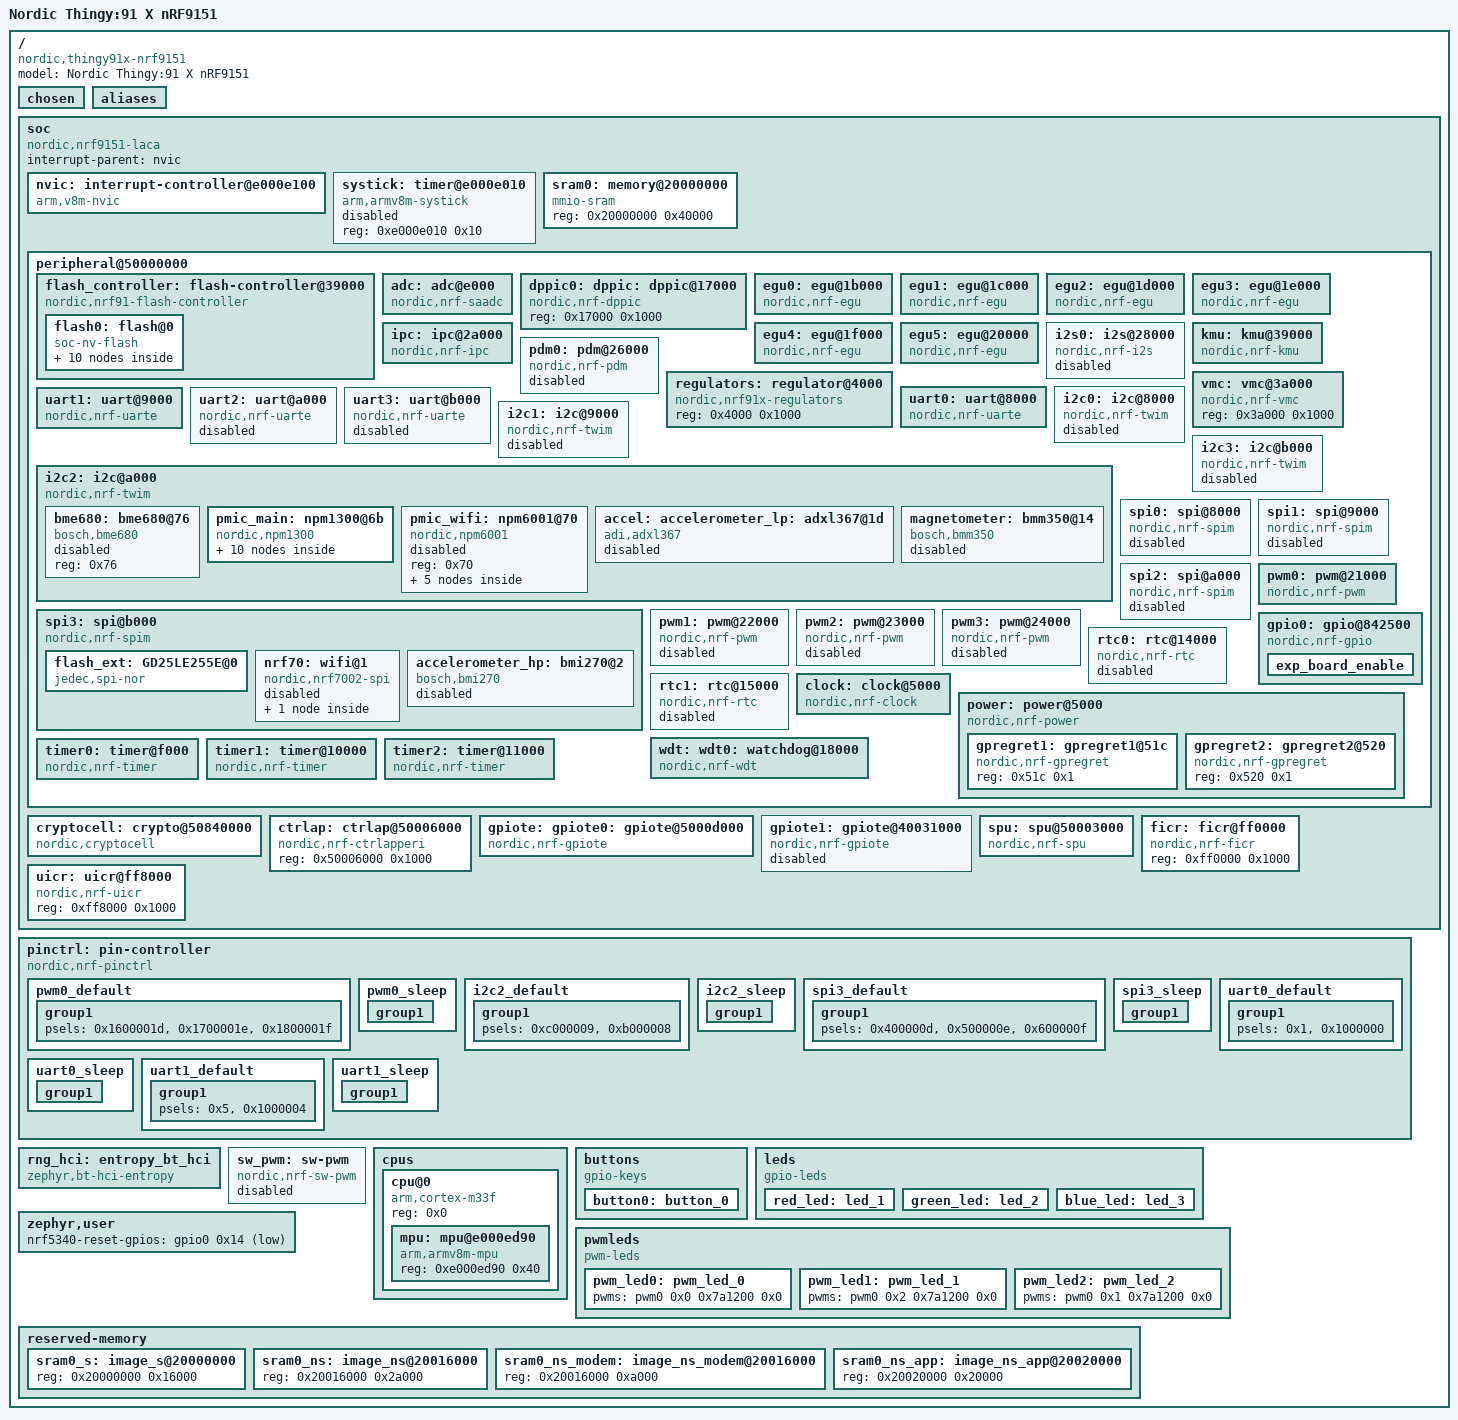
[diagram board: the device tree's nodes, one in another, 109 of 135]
/dts-v1/;

/ {
	#address-cells = < 0x1 >;
	#size-cells = < 0x1 >;
	model = "Nordic Thingy:91 X nRF9151";
	compatible = "nordic,thingy91x-nrf9151";
	chosen {
		zephyr,entropy = &cryptocell;
		zephyr,flash-controller = &flash_controller;
		zephyr,console = &uart0;
		zephyr,shell-uart = &uart0;
		zephyr,uart-mcumgr = &uart0;
		nordic,pm-ext-flash = &flash_ext;
		zephyr,sram = &sram0;
		zephyr,flash = &flash0;
		zephyr,code-partition = &slot0_partition;
		zephyr,wifi = &nordic_wlan0;
	};
	aliases {
		sw0 = &button0;
		led0 = &red_led;
		led1 = &green_led;
		led2 = &blue_led;
		pwm-led0 = &pwm_led0;
		pwm-led1 = &pwm_led1;
		pwm-led2 = &pwm_led2;
		rgb-pwm = &pwm0;
		mcuboot-button0 = &button0;
		spi-flash0 = &flash_ext;
	};
	soc {
		#address-cells = < 0x1 >;
		#size-cells = < 0x1 >;
		compatible = "nordic,nrf9151-laca", "nordic,nrf9120", "nordic,nrf91", "simple-bus";
		interrupt-parent = < &nvic >;
		ranges;
		nvic: interrupt-controller@e000e100 {
			#address-cells = < 0x1 >;
			compatible = "arm,v8m-nvic";
			reg = < 0xe000e100 0xc00 >;
			interrupt-controller;
			#interrupt-cells = < 0x2 >;
			arm,num-irq-priority-bits = < 0x3 >;
			phandle = < 0x1 >;
		};
		systick: timer@e000e010 {
			compatible = "arm,armv8m-systick";
			reg = < 0xe000e010 0x10 >;
			status = "disabled";
		};
		sram0: memory@20000000 {
			compatible = "mmio-sram";
			reg = < 0x20000000 0x40000 >;
		};
		peripheral@50000000 {
			#address-cells = < 0x1 >;
			#size-cells = < 0x1 >;
			ranges = < 0x0 0x50000000 0x10000000 >;
			flash_controller: flash-controller@39000 {
				compatible = "nordic,nrf91-flash-controller";
				reg = < 0x39000 0x1000 >;
				partial-erase;
				#address-cells = < 0x1 >;
				#size-cells = < 0x1 >;
				flash0: flash@0 {
					compatible = "soc-nv-flash";
					erase-block-size = < 0x1000 >;
					write-block-size = < 0x4 >;
					reg = < 0x0 0x100000 >;
					partitions {
						compatible = "fixed-partitions";
						#address-cells = < 0x1 >;
						#size-cells = < 0x1 >;
						boot_partition: partition@0 {
							label = "mcuboot";
							reg = < 0x0 0x10000 >;
						};
						slot0_partition: partition@10000 {
							label = "image-0";
							reg = < 0x10000 0x40000 >;
						};
						slot0_ns_partition: partition@50000 {
							label = "image-0-nonsecure";
							reg = < 0x50000 0x30000 >;
						};
						slot1_partition: partition@80000 {
							label = "image-1";
							reg = < 0x80000 0x40000 >;
						};
						slot1_ns_partition: partition@c0000 {
							label = "image-1-nonsecure";
							reg = < 0xc0000 0x30000 >;
						};
						tfm_ps_partition: partition@f0000 {
							label = "tfm-ps";
							reg = < 0xf0000 0x4000 >;
						};
						tfm_its_partition: partition@f4000 {
							label = "tfm-its";
							reg = < 0xf4000 0x2000 >;
						};
						tfm_otp_partition: partition@f6000 {
							label = "tfm-otp";
							reg = < 0xf6000 0x2000 >;
						};
						storage_partition: partition@f8000 {
							label = "storage";
							reg = < 0xf8000 0x8000 >;
						};
					};
				};
			};
			adc: adc@e000 {
				compatible = "nordic,nrf-saadc";
				reg = < 0xe000 0x1000 >;
				interrupts = < 0xe 0x1 >;
				status = "okay";
				#io-channel-cells = < 0x1 >;
				zephyr,pm-device-runtime-auto;
			};
			dppic0: dppic: dppic@17000 {
				compatible = "nordic,nrf-dppic";
				reg = < 0x17000 0x1000 >;
				status = "okay";
			};
			egu0: egu@1b000 {
				compatible = "nordic,nrf-egu";
				reg = < 0x1b000 0x1000 >;
				interrupts = < 0x1b 0x1 >;
				status = "okay";
			};
			egu1: egu@1c000 {
				compatible = "nordic,nrf-egu";
				reg = < 0x1c000 0x1000 >;
				interrupts = < 0x1c 0x1 >;
				status = "okay";
			};
			egu2: egu@1d000 {
				compatible = "nordic,nrf-egu";
				reg = < 0x1d000 0x1000 >;
				interrupts = < 0x1d 0x1 >;
				status = "okay";
			};
			egu3: egu@1e000 {
				compatible = "nordic,nrf-egu";
				reg = < 0x1e000 0x1000 >;
				interrupts = < 0x1e 0x1 >;
				status = "okay";
			};
			egu4: egu@1f000 {
				compatible = "nordic,nrf-egu";
				reg = < 0x1f000 0x1000 >;
				interrupts = < 0x1f 0x1 >;
				status = "okay";
			};
			egu5: egu@20000 {
				compatible = "nordic,nrf-egu";
				reg = < 0x20000 0x1000 >;
				interrupts = < 0x20 0x1 >;
				status = "okay";
			};
			ipc: ipc@2a000 {
				compatible = "nordic,nrf-ipc";
				reg = < 0x2a000 0x1000 >;
				interrupts = < 0x2a 0x1 >;
				status = "okay";
			};
			i2s0: i2s@28000 {
				compatible = "nordic,nrf-i2s";
				#address-cells = < 0x1 >;
				#size-cells = < 0x0 >;
				reg = < 0x28000 0x1000 >;
				interrupts = < 0x28 0x1 >;
				status = "disabled";
			};
			kmu: kmu@39000 {
				compatible = "nordic,nrf-kmu";
				reg = < 0x39000 0x1000 >;
				interrupts = < 0x39 0x1 >;
				status = "okay";
			};
			pdm0: pdm@26000 {
				compatible = "nordic,nrf-pdm";
				reg = < 0x26000 0x1000 >;
				interrupts = < 0x26 0x1 >;
				status = "disabled";
			};
			regulators: regulator@4000 {
				compatible = "nordic,nrf91x-regulators";
				reg = < 0x4000 0x1000 >;
				status = "okay";
			};
			vmc: vmc@3a000 {
				compatible = "nordic,nrf-vmc";
				reg = < 0x3a000 0x1000 >;
				status = "okay";
			};
			uart0: uart@8000 {
				compatible = "nordic,nrf-uarte";
				reg = < 0x8000 0x1000 >;
				interrupts = < 0x8 0x1 >;
				status = "okay";
				current-speed = < 0x1c200 >;
				pinctrl-0 = < &uart0_default >;
				pinctrl-1 = < &uart0_sleep >;
				pinctrl-names = "default", "sleep";
			};
			uart1: uart@9000 {
				compatible = "nordic,nrf-uarte";
				reg = < 0x9000 0x1000 >;
				interrupts = < 0x9 0x1 >;
				status = "okay";
				current-speed = < 0xf4240 >;
				pinctrl-0 = < &uart1_default >;
				pinctrl-1 = < &uart1_sleep >;
				pinctrl-names = "default", "sleep";
			};
			uart2: uart@a000 {
				compatible = "nordic,nrf-uarte";
				reg = < 0xa000 0x1000 >;
				interrupts = < 0xa 0x1 >;
				status = "disabled";
			};
			uart3: uart@b000 {
				compatible = "nordic,nrf-uarte";
				reg = < 0xb000 0x1000 >;
				interrupts = < 0xb 0x1 >;
				status = "disabled";
			};
			i2c0: i2c@8000 {
				compatible = "nordic,nrf-twim";
				#address-cells = < 0x1 >;
				#size-cells = < 0x0 >;
				reg = < 0x8000 0x1000 >;
				interrupts = < 0x8 0x1 >;
				easydma-maxcnt-bits = < 0xd >;
				status = "disabled";
				zephyr,pm-device-runtime-auto;
			};
			i2c1: i2c@9000 {
				compatible = "nordic,nrf-twim";
				#address-cells = < 0x1 >;
				#size-cells = < 0x0 >;
				reg = < 0x9000 0x1000 >;
				interrupts = < 0x9 0x1 >;
				easydma-maxcnt-bits = < 0xd >;
				status = "disabled";
				zephyr,pm-device-runtime-auto;
			};
			i2c2: i2c@a000 {
				compatible = "nordic,nrf-twim";
				#address-cells = < 0x1 >;
				#size-cells = < 0x0 >;
				reg = < 0xa000 0x1000 >;
				interrupts = < 0xa 0x1 >;
				easydma-maxcnt-bits = < 0xd >;
				status = "okay";
				zephyr,pm-device-runtime-auto;
				clock-frequency = < 0x186a0 >;
				pinctrl-0 = < &i2c2_default >;
				pinctrl-1 = < &i2c2_sleep >;
				pinctrl-names = "default", "sleep";
				bme680: bme680@76 {
					status = "disabled";
					compatible = "bosch,bme680";
					reg = < 0x76 >;
				};
				pmic_main: npm1300@6b {
					compatible = "nordic,npm1300";
					status = "okay";
					pmic-int-pin = < 0x3 >;
					reg = < 0x6b >;
					host-int-gpios = < &gpio0 0x2 0x0 >;
					gpios_pmic: npm1300_gpios {
						compatible = "nordic,npm1300-gpio";
						status = "okay";
						gpio-controller;
						#gpio-cells = < 0x2 >;
						ngpios = < 0x5 >;
						phandle = < 0x9 >;
						npm13_button: GPIO0 {
							gpio-hog;
							gpios = < 0x0 0x0 >;
						};
						ldsw_rf_fe_sr_en: GPIO1 {
							gpio-hog;
							output-low;
							gpios = < 0x1 0x17 >;
						};
						power_switch: GPIO2 {
							gpio-hog;
							gpios = < 0x2 0x0 >;
						};
						npm6001_ready: GPIO4 {
							gpio-hog;
							gpios = < 0x4 0x0 >;
						};
					};
					regulators {
						compatible = "nordic,npm1300-regulator";
						status = "okay";
						reg_3v3: BUCK2 {
							regulator-min-microvolt = < 0x325aa0 >;
							regulator-max-microvolt = < 0x325aa0 >;
							enable-gpios = < &gpios_pmic 0x2 0x0 >;
						};
						ldsw_nPM6001_en: LDO1 {
							regulator-initial-mode = < 0x3 >;
							regulator-allowed-modes = < 0x3 >;
							regulator-boot-off;
						};
						ldsw_sensors: LDO2 {
							regulator-initial-mode = < 0x3 >;
							regulator-allowed-modes = < 0x3 >;
							regulator-boot-on;
						};
					};
					npm1300_charger: charger {
						compatible = "nordic,npm1300-charger";
						status = "okay";
						vbus-limit-microamp = < 0x7a120 >;
						term-microvolt = < 0x401640 >;
						current-microamp = < 0xa4cb8 >;
						dischg-limit-microamp = < 0xf4240 >;
						thermistor-cold-millidegrees = < 0x0 >;
						thermistor-cool-millidegrees = < 0x0 >;
						thermistor-warm-millidegrees = < 0xafc8 >;
						thermistor-hot-millidegrees = < 0xafc8 >;
						thermistor-ohms = < 0x2710 >;
						thermistor-beta = < 0xd6b >;
						charging-enable;
					};
				};
				pmic_wifi: npm6001@70 {
					status = "disabled";
					compatible = "nordic,npm6001";
					reg = < 0x70 >;
					regulators {
						compatible = "nordic,npm6001-regulator";
						status = "disabled";
						pmic_wifi_buck0: BUCK0 {
							regulator-boot-off;
						};
						pmic_wifi_buck1: BUCK1 {
							regulator-boot-off;
						};
						pmic_wifi_buck2: BUCK2 {
							regulator-boot-off;
						};
						reg_wifi: BUCK3 {
							regulator-min-microvolt = < 0x325aa0 >;
							regulator-max-microvolt = < 0x325aa0 >;
							regulator-initial-mode = < 0x0 >;
							regulator-boot-on;
						};
					};
				};
				accel: accelerometer_lp: adxl367@1d {
					status = "disabled";
					compatible = "adi,adxl367";
					odr = < 0x3 >;
					reg = < 0x1d >;
					int1-gpios = < &gpio0 0xb 0x0 >;
				};
				magnetometer: bmm350@14 {
					status = "disabled";
					compatible = "bosch,bmm350";
					reg = < 0x14 >;
					drdy-gpios = < &gpio0 0x7 0x1 >;
				};
			};
			i2c3: i2c@b000 {
				compatible = "nordic,nrf-twim";
				#address-cells = < 0x1 >;
				#size-cells = < 0x0 >;
				reg = < 0xb000 0x1000 >;
				interrupts = < 0xb 0x1 >;
				easydma-maxcnt-bits = < 0xd >;
				status = "disabled";
				zephyr,pm-device-runtime-auto;
			};
			spi0: spi@8000 {
				compatible = "nordic,nrf-spim";
				#address-cells = < 0x1 >;
				#size-cells = < 0x0 >;
				reg = < 0x8000 0x1000 >;
				interrupts = < 0x8 0x1 >;
				max-frequency = < 0x7a1200 >;
				easydma-maxcnt-bits = < 0xd >;
				status = "disabled";
			};
			spi1: spi@9000 {
				compatible = "nordic,nrf-spim";
				#address-cells = < 0x1 >;
				#size-cells = < 0x0 >;
				reg = < 0x9000 0x1000 >;
				interrupts = < 0x9 0x1 >;
				max-frequency = < 0x7a1200 >;
				easydma-maxcnt-bits = < 0xd >;
				status = "disabled";
			};
			spi2: spi@a000 {
				compatible = "nordic,nrf-spim";
				#address-cells = < 0x1 >;
				#size-cells = < 0x0 >;
				reg = < 0xa000 0x1000 >;
				interrupts = < 0xa 0x1 >;
				max-frequency = < 0x7a1200 >;
				easydma-maxcnt-bits = < 0xd >;
				status = "disabled";
			};
			spi3: spi@b000 {
				compatible = "nordic,nrf-spim";
				#address-cells = < 0x1 >;
				#size-cells = < 0x0 >;
				reg = < 0xb000 0x1000 >;
				interrupts = < 0xb 0x1 >;
				max-frequency = < 0x7a1200 >;
				easydma-maxcnt-bits = < 0xd >;
				status = "okay";
				pinctrl-0 = < &spi3_default >;
				pinctrl-1 = < &spi3_sleep >;
				pinctrl-names = "default", "sleep";
				cs-gpios = < &gpio0 0xc 0x1 >, < &gpio0 0x11 0x1 >, < &gpio0 0xa 0x1 >;
				flash_ext: GD25LE255E@0 {
					compatible = "jedec,spi-nor";
					status = "okay";
					reg = < 0x0 >;
					spi-max-frequency = < 0x7a1200 >;
					size = < 0x10000000 >;
					has-dpd;
					t-enter-dpd = < 0xbb8 >;
					t-exit-dpd = < 0x4e20 >;
					sfdp-bfp = [ E5 20 F3 FF FF FF FF 0F 44 EB 08 6B 08 3B 42 BB FE FF FF FF FF FF 00 FF FF FF 42 EB 0C 20 0F 52 10 D8 00 FF D4 31 A5 FE 84 DF 14 4F EC 62 16 33 7A 75 7A 75 04 B3 D5 5C 19 06 14 00 08 50 00 01 ];
					jedec-id = [ C8 60 19 ];
				};
				nrf70: wifi@1 {
					compatible = "nordic,nrf7002-spi";
					status = "disabled";
					reg = < 0x1 >;
					spi-max-frequency = < 0x7a1200 >;
					iovdd-ctrl-gpios = < &gpio0 0x1b 0x20 >;
					bucken-gpios = < &gpio0 0x1c 0x20 >;
					host-irq-gpios = < &gpio0 0x10 0x0 >;
					wifi-max-tx-pwr-2g-dsss = < 0x15 >;
					wifi-max-tx-pwr-2g-mcs0 = < 0x10 >;
					wifi-max-tx-pwr-2g-mcs7 = < 0x10 >;
					wifi-max-tx-pwr-5g-low-mcs0 = < 0x9 >;
					wifi-max-tx-pwr-5g-low-mcs7 = < 0x9 >;
					wifi-max-tx-pwr-5g-mid-mcs0 = < 0xb >;
					wifi-max-tx-pwr-5g-mid-mcs7 = < 0xb >;
					wifi-max-tx-pwr-5g-high-mcs0 = < 0xd >;
					wifi-max-tx-pwr-5g-high-mcs7 = < 0xd >;
					nordic_wlan0: wlan0 {
						compatible = "nordic,wlan";
					};
				};
				accelerometer_hp: bmi270@2 {
					compatible = "bosch,bmi270";
					status = "disabled";
					reg = < 0x2 >;
					spi-max-frequency = < 0x989680 >;
					irq-gpios = < &gpio0 0x6 0x1 >;
				};
			};
			pwm0: pwm@21000 {
				compatible = "nordic,nrf-pwm";
				reg = < 0x21000 0x1000 >;
				interrupts = < 0x21 0x1 >;
				status = "okay";
				#pwm-cells = < 0x3 >;
				pinctrl-0 = < &pwm0_default >;
				pinctrl-1 = < &pwm0_sleep >;
				pinctrl-names = "default", "sleep";
				phandle = < 0x10 >;
			};
			pwm1: pwm@22000 {
				compatible = "nordic,nrf-pwm";
				reg = < 0x22000 0x1000 >;
				interrupts = < 0x22 0x1 >;
				status = "disabled";
				#pwm-cells = < 0x3 >;
			};
			pwm2: pwm@23000 {
				compatible = "nordic,nrf-pwm";
				reg = < 0x23000 0x1000 >;
				interrupts = < 0x23 0x1 >;
				status = "disabled";
				#pwm-cells = < 0x3 >;
			};
			pwm3: pwm@24000 {
				compatible = "nordic,nrf-pwm";
				reg = < 0x24000 0x1000 >;
				interrupts = < 0x24 0x1 >;
				status = "disabled";
				#pwm-cells = < 0x3 >;
			};
			gpio0: gpio@842500 {
				compatible = "nordic,nrf-gpio";
				gpio-controller;
				reg = < 0x842500 0x300 >;
				#gpio-cells = < 0x2 >;
				status = "okay";
				port = < 0x0 >;
				gpiote-instance = < &gpiote >;
				sense-edge-mask = < 0xffffffff >;
				phandle = < 0x8 >;
				exp_board_enable: exp_board_enable {
					gpio-hog;
					output-low;
					gpios = < 0x3 0x0 >;
				};
			};
			rtc0: rtc@14000 {
				compatible = "nordic,nrf-rtc";
				reg = < 0x14000 0x1000 >;
				cc-num = < 0x4 >;
				interrupts = < 0x14 0x1 >;
				status = "disabled";
				clock-frequency = < 0x8000 >;
				prescaler = < 0x1 >;
			};
			rtc1: rtc@15000 {
				compatible = "nordic,nrf-rtc";
				reg = < 0x15000 0x1000 >;
				cc-num = < 0x4 >;
				interrupts = < 0x15 0x1 >;
				status = "disabled";
				clock-frequency = < 0x8000 >;
				prescaler = < 0x1 >;
			};
			clock: clock@5000 {
				compatible = "nordic,nrf-clock";
				reg = < 0x5000 0x1000 >;
				interrupts = < 0x5 0x1 >;
				status = "okay";
			};
			power: power@5000 {
				compatible = "nordic,nrf-power";
				reg = < 0x5000 0x1000 >;
				ranges = < 0x0 0x5000 0x1000 >;
				interrupts = < 0x5 0x1 >;
				status = "okay";
				#address-cells = < 0x1 >;
				#size-cells = < 0x1 >;
				gpregret1: gpregret1@51c {
					#address-cells = < 0x1 >;
					#size-cells = < 0x1 >;
					compatible = "nordic,nrf-gpregret";
					reg = < 0x51c 0x1 >;
					status = "okay";
				};
				gpregret2: gpregret2@520 {
					#address-cells = < 0x1 >;
					#size-cells = < 0x1 >;
					compatible = "nordic,nrf-gpregret";
					reg = < 0x520 0x1 >;
					status = "okay";
				};
			};
			wdt: wdt0: watchdog@18000 {
				compatible = "nordic,nrf-wdt";
				reg = < 0x18000 0x1000 >;
				interrupts = < 0x18 0x1 >;
				status = "okay";
			};
			timer0: timer@f000 {
				compatible = "nordic,nrf-timer";
				status = "okay";
				reg = < 0xf000 0x1000 >;
				cc-num = < 0x6 >;
				max-bit-width = < 0x20 >;
				interrupts = < 0xf 0x1 >;
				prescaler = < 0x0 >;
			};
			timer1: timer@10000 {
				compatible = "nordic,nrf-timer";
				status = "okay";
				reg = < 0x10000 0x1000 >;
				cc-num = < 0x6 >;
				max-bit-width = < 0x20 >;
				interrupts = < 0x10 0x1 >;
				prescaler = < 0x0 >;
				phandle = < 0xf >;
			};
			timer2: timer@11000 {
				compatible = "nordic,nrf-timer";
				status = "okay";
				reg = < 0x11000 0x1000 >;
				cc-num = < 0x6 >;
				max-bit-width = < 0x20 >;
				interrupts = < 0x11 0x1 >;
				prescaler = < 0x0 >;
			};
		};
		cryptocell: crypto@50840000 {
			compatible = "nordic,cryptocell", "arm,cryptocell-310";
			reg = < 0x50840000 0x1000 >, < 0x50841000 0x1000 >;
			reg-names = "wrapper", "core";
			interrupts = < 0x40 0x1 >;
			status = "okay";
		};
		ctrlap: ctrlap@50006000 {
			compatible = "nordic,nrf-ctrlapperi";
			reg = < 0x50006000 0x1000 >;
			status = "okay";
		};
		gpiote: gpiote0: gpiote@5000d000 {
			compatible = "nordic,nrf-gpiote";
			reg = < 0x5000d000 0x1000 >;
			interrupts = < 0xd 0x5 >;
			status = "okay";
			instance = < 0x0 >;
			phandle = < 0xe >;
		};
		gpiote1: gpiote@40031000 {
			compatible = "nordic,nrf-gpiote";
			reg = < 0x40031000 0x1000 >;
			interrupts = < 0x31 0x5 >;
			status = "disabled";
			instance = < 0x1 >;
		};
		spu: spu@50003000 {
			compatible = "nordic,nrf-spu";
			reg = < 0x50003000 0x1000 >;
			interrupts = < 0x3 0x1 >;
			status = "okay";
		};
		ficr: ficr@ff0000 {
			compatible = "nordic,nrf-ficr";
			reg = < 0xff0000 0x1000 >;
			#nordic,ficr-cells = < 0x1 >;
			status = "okay";
		};
		uicr: uicr@ff8000 {
			compatible = "nordic,nrf-uicr";
			reg = < 0xff8000 0x1000 >;
			status = "okay";
		};
	};
	pinctrl: pin-controller {
		compatible = "nordic,nrf-pinctrl";
		pwm0_default: pwm0_default {
			phandle = < 0xc >;
			group1 {
				psels = < 0x1600001d >, < 0x1700001e >, < 0x1800001f >;
			};
		};
		pwm0_sleep: pwm0_sleep {
			phandle = < 0xd >;
			group1 {
				psels = < 0x1600001d >, < 0x1700001e >, < 0x1800001f >;
				low-power-enable;
			};
		};
		i2c2_default: i2c2_default {
			phandle = < 0x6 >;
			group1 {
				psels = < 0xc000009 >, < 0xb000008 >;
			};
		};
		i2c2_sleep: i2c2_sleep {
			phandle = < 0x7 >;
			group1 {
				psels = < 0xc000009 >, < 0xb000008 >;
				low-power-enable;
			};
		};
		spi3_default: spi3_default {
			phandle = < 0xa >;
			group1 {
				psels = < 0x400000d >, < 0x500000e >, < 0x600000f >;
			};
		};
		spi3_sleep: spi3_sleep {
			phandle = < 0xb >;
			group1 {
				psels = < 0x400000d >, < 0x500000e >, < 0x600000f >;
				low-power-enable;
			};
		};
		uart0_default: uart0_default {
			phandle = < 0x2 >;
			group1 {
				psels = < 0x1 >, < 0x1000000 >;
			};
		};
		uart0_sleep: uart0_sleep {
			phandle = < 0x3 >;
			group1 {
				psels = < 0x1 >, < 0x1000000 >;
				low-power-enable;
			};
		};
		uart1_default: uart1_default {
			phandle = < 0x4 >;
			group1 {
				psels = < 0x5 >, < 0x1000004 >;
			};
		};
		uart1_sleep: uart1_sleep {
			phandle = < 0x5 >;
			group1 {
				psels = < 0x5 >, < 0x1000004 >;
				low-power-enable;
			};
		};
	};
	rng_hci: entropy_bt_hci {
		compatible = "zephyr,bt-hci-entropy";
		status = "okay";
	};
	sw_pwm: sw-pwm {
		compatible = "nordic,nrf-sw-pwm";
		status = "disabled";
		generator = < &timer1 >;
		clock-prescaler = < 0x0 >;
		#pwm-cells = < 0x3 >;
	};
	cpus {
		#address-cells = < 0x1 >;
		#size-cells = < 0x0 >;
		cpu@0 {
			device_type = "cpu";
			compatible = "arm,cortex-m33f";
			reg = < 0x0 >;
			#address-cells = < 0x1 >;
			#size-cells = < 0x1 >;
			mpu: mpu@e000ed90 {
				compatible = "arm,armv8m-mpu";
				reg = < 0xe000ed90 0x40 >;
			};
		};
	};
	buttons {
		compatible = "gpio-keys";
		button0: button_0 {
			gpios = < &gpio0 0x1a 0x11 >;
			label = "Button 1";
		};
	};
	leds {
		compatible = "gpio-leds";
		red_led: led_1 {
			gpios = < &gpio0 0x1d 0x0 >;
			label = "RGB red channel";
		};
		green_led: led_2 {
			gpios = < &gpio0 0x1f 0x0 >;
			label = "RGB green channel";
		};
		blue_led: led_3 {
			gpios = < &gpio0 0x1e 0x0 >;
			label = "RGB blue channel";
		};
	};
	pwmleds {
		compatible = "pwm-leds";
		pwm_led0: pwm_led_0 {
			pwms = < &pwm0 0x0 0x7a1200 0x0 >;
		};
		pwm_led1: pwm_led_1 {
			pwms = < &pwm0 0x2 0x7a1200 0x0 >;
		};
		pwm_led2: pwm_led_2 {
			pwms = < &pwm0 0x1 0x7a1200 0x0 >;
		};
	};
	zephyr,user {
		nrf5340-reset-gpios = < &gpio0 0x14 0x1 >;
	};
	reserved-memory {
		#address-cells = < 0x1 >;
		#size-cells = < 0x1 >;
		ranges;
		sram0_s: image_s@20000000 {
			reg = < 0x20000000 0x16000 >;
		};
		sram0_ns: image_ns@20016000 {
			reg = < 0x20016000 0x2a000 >;
		};
		sram0_ns_modem: image_ns_modem@20016000 {
			reg = < 0x20016000 0xa000 >;
		};
		sram0_ns_app: image_ns_app@20020000 {
			reg = < 0x20020000 0x20000 >;
		};
	};
};
